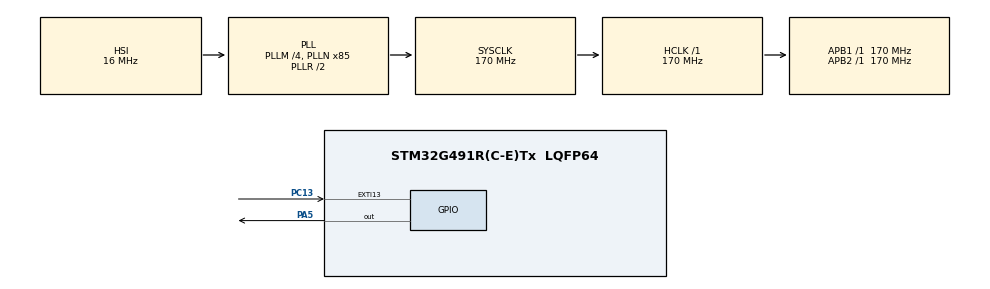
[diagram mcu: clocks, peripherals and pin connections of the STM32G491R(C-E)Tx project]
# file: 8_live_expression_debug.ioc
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Mcu.Family=STM32G4
Mcu.Name=STM32G491R(C-E)Tx
Mcu.Package=LQFP64
NUCLEO-G491RE.BUTTON=1
NUCLEO-G491RE.LD2=true
NUCLEO-G491RE.VCP=true
NVIC.EXTI15_10_IRQn=true\:0\:0\:false\:false\:true\:true\:true\:true
NVIC.PriorityGroup=NVIC_PRIORITYGROUP_4
PA13.GPIO_Label=T_SWDIO
PA13.Signal=SYS_JTMS-SWDIO
PA14.GPIO_Label=T_SWCLK
PA14.Signal=SYS_JTCK-SWCLK
PA2.Signal=LPUART1_TX
PA3.Signal=LPUART1_RX
PA5.Signal=GPIO_Output
PB3.GPIO_Label=T_SWO
PB3.Signal=SYS_JTDO-SWO
PC13.Signal=GPXTI13
PC14-OSC32_IN.GPIO_Label=RCC_OSC32_IN
PC14-OSC32_IN.Signal=RCC_OSC32_IN
PC15-OSC32_OUT.GPIO_Label=RCC_OSC32_OUT
PC15-OSC32_OUT.Signal=RCC_OSC32_OUT
PF0-OSC_IN.GPIO_Label=RCC_OSC_IN
PF0-OSC_IN.Signal=RCC_OSC_IN
PF1-OSC_OUT.GPIO_Label=RCC_OSC_OUT
PF1-OSC_OUT.Signal=RCC_OSC_OUT
ProjectManager.HeapSize=0x200
ProjectManager.StackSize=0x400
ProjectManager.TargetToolchain=STM32CubeIDE
RCC.ADC12Freq_Value=170000000
RCC.ADC345Freq_Value=170000000
RCC.AHBFreq_Value=170000000
RCC.APB1Freq_Value=170000000
RCC.APB1TimFreq_Value=170000000
RCC.APB2Freq_Value=170000000
RCC.APB2TimFreq_Value=170000000
RCC.CortexFreq_Value=170000000
RCC.EXTERNAL_CLOCK_VALUE=12288000
RCC.HCLKFreq_Value=170000000
RCC.HSE_VALUE=24000000
RCC.HSI48_VALUE=48000000
RCC.HSI_VALUE=16000000
RCC.LSE_VALUE=32768
RCC.PLLM=RCC_PLLM_DIV4
RCC.PLLN=85
RCC.RTCClockSelection=RCC_RTCCLKSOURCE_LSE
RCC.SYSCLKFreq_VALUE=170000000
RCC.SYSCLKSource=RCC_SYSCLKSOURCE_PLLCLK
RCC.USBFreq_Value=48000000
RCC.VCOOutputFreq_Value=340000000
VP_NUCLEO-G491RE_VS_BSP_COMMON.Mode=COMMON
VP_SYS_VS_DBSignals.Mode=DisableDeadBatterySignals
board=NUCLEO-G491RE

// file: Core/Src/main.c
/* USER CODE BEGIN Header */
/**
  ******************************************************************************
  * @file           : main.c
  * @brief          : Main program body
  ******************************************************************************
  * @attention
  *
  * Copyright (c) 2025 STMicroelectronics.
  * All rights reserved.
  *
  * This software is licensed under terms that can be found in the LICENSE file
  * in the root directory of this software component.
  * If no LICENSE file comes with this software, it is provided AS-IS.
  *
  ******************************************************************************
  */
/* USER CODE END Header */
#include "main.h"

COM_InitTypeDef BspCOMInit;

void SystemClock_Config(void);
static void MX_GPIO_Init(void);

uint16_t counter = 0;
int main(void)
{

  /* MCU Configuration--------------------------------------------------------*/

  /* Reset of all peripherals, Initializes the Flash interface and the Systick. */
  HAL_Init();

  /* Configure the system clock */
  SystemClock_Config();

  /* Initialize all configured peripherals */
  MX_GPIO_Init();

  /* Initialize led */
  BSP_LED_Init(LED_GREEN);

  /* Initialize USER push-button, will be used to trigger an interrupt each time it's pressed.*/
  BSP_PB_Init(BUTTON_USER, BUTTON_MODE_EXTI);

  /* Initialize COM1 port (115200, 8 bits (7-bit data + 1 stop bit), no parity */
  BspCOMInit.BaudRate   = 115200;
  BspCOMInit.WordLength = COM_WORDLENGTH_8B;
  BspCOMInit.StopBits   = COM_STOPBITS_1;
  BspCOMInit.Parity     = COM_PARITY_NONE;
  BspCOMInit.HwFlowCtl  = COM_HWCONTROL_NONE;
  if (BSP_COM_Init(COM1, &BspCOMInit) != BSP_ERROR_NONE)
  {
    Error_Handler();
  }

  /* Infinite loop */
  /* USER CODE BEGIN WHILE */
  while (1)
  {
	  counter++;
	  HAL_Delay(2000);

    /* USER CODE END WHILE */

  }
}

void SystemClock_Config(void)
{
  RCC_OscInitTypeDef RCC_OscInitStruct = {0};
  RCC_ClkInitTypeDef RCC_ClkInitStruct = {0};

  /** Configure the main internal regulator output voltage
  */
  HAL_PWREx_ControlVoltageScaling(PWR_REGULATOR_VOLTAGE_SCALE1_BOOST);

  /** Initializes the RCC Oscillators according to the specified parameters
  * in the RCC_OscInitTypeDef structure.
  */
  RCC_OscInitStruct.OscillatorType = RCC_OSCILLATORTYPE_HSI;
  RCC_OscInitStruct.HSIState = RCC_HSI_ON;
  RCC_OscInitStruct.HSICalibrationValue = RCC_HSICALIBRATION_DEFAULT;
  RCC_OscInitStruct.PLL.PLLState = RCC_PLL_ON;
  RCC_OscInitStruct.PLL.PLLSource = RCC_PLLSOURCE_HSI;
  RCC_OscInitStruct.PLL.PLLM = RCC_PLLM_DIV4;
  RCC_OscInitStruct.PLL.PLLN = 85;
  RCC_OscInitStruct.PLL.PLLP = RCC_PLLP_DIV2;
  RCC_OscInitStruct.PLL.PLLQ = RCC_PLLQ_DIV2;
  RCC_OscInitStruct.PLL.PLLR = RCC_PLLR_DIV2;
  if (HAL_RCC_OscConfig(&RCC_OscInitStruct) != HAL_OK)
  {
    Error_Handler();
  }

  /** Initializes the CPU, AHB and APB buses clocks
  */
  RCC_ClkInitStruct.ClockType = RCC_CLOCKTYPE_HCLK|RCC_CLOCKTYPE_SYSCLK
                              |RCC_CLOCKTYPE_PCLK1|RCC_CLOCKTYPE_PCLK2;
  RCC_ClkInitStruct.SYSCLKSource = RCC_SYSCLKSOURCE_PLLCLK;
  RCC_ClkInitStruct.AHBCLKDivider = RCC_SYSCLK_DIV1;
  RCC_ClkInitStruct.APB1CLKDivider = RCC_HCLK_DIV1;
  RCC_ClkInitStruct.APB2CLKDivider = RCC_HCLK_DIV1;

  if (HAL_RCC_ClockConfig(&RCC_ClkInitStruct, FLASH_LATENCY_4) != HAL_OK)
  {
    Error_Handler();
  }
}

static void MX_GPIO_Init(void)
{

  /* GPIO Ports Clock Enable */
  __HAL_RCC_GPIOC_CLK_ENABLE();
  __HAL_RCC_GPIOF_CLK_ENABLE();
  __HAL_RCC_GPIOA_CLK_ENABLE();
  __HAL_RCC_GPIOB_CLK_ENABLE();

}

void Error_Handler(void)
{
  __disable_irq();
  while (1)
  {
  }
}
